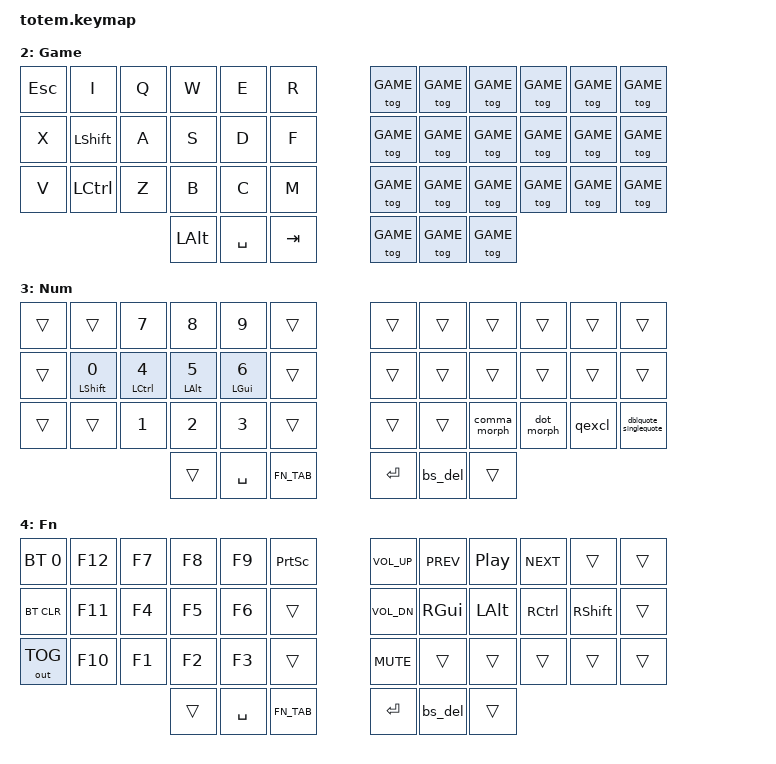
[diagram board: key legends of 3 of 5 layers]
/*
 * Zenith-ZMK Keymap
 * 42-key TOTEM variant with advanced features
 *
 * Features:
 * - Timeless homerow mods (GACS on home row)
 * - Smart num layer (num_word auto-toggle)
 * - Magic shift (repeat/sticky/capsword)
 * - Symbol combos (no dedicated symbol layer needed)
 * - Leader key sequences
 * - Gaming layer (WASD, no homerow mods)
 *
 * Layers:
 *   0 - DEF    : Base QWERTY with homerow mods
 *   1 - NAV    : Navigation, editing, media
 *   2 - GAME : Gaming (QWERTY left, no HRMs)
 *   3 - NUM    : Numbers and function keys
 *   4 - FN     : Function (reserved for future use)
 */

#include <behaviors.dtsi>
#include <behaviors/num_word.dtsi>
#include <dt-bindings/zmk/keys.h>
#include <dt-bindings/zmk/bt.h>
#include <dt-bindings/zmk/outputs.h>

/* Key position labels for 42-key layout */
#include "key-labels-42.h"

/* Swedish keyboard layout support */
#include "swedish-keys.h"

/* Layer definitions */
#define DEF 0
#define NAV 1
#define GAME 2
#define NUM 3
#define FN 4

/* Convenience aliases */
#define XXX &none
#define ___ &trans

/* Include custom behaviors, combos, and leader sequences */
#include "behaviors.dtsi"
#include "combos.dtsi"
#include "leader.dtsi"

/ {
    keymap {
        compatible = "zmk,keymap";

        /*
         * Base Layer (DEF) - QWERTY with Homerow Mods
         *
         * ╭──────┬──────┬──────┬──────┬──────┬──────╮   ╭──────┬──────┬──────┬──────┬──────┬──────╮
         * │ ESC  │  Q   │  W   │  E   │  R   │  T   │   │  Y   │  U   │  I   │  O   │  P   │  Å   │
         * ├──────┼──────┼──────┼──────┼──────┼──────┤   ├──────┼──────┼──────┼──────┼──────┼──────┤
         * │ SNIP │  A   │  S   │  D   │  F   │  G   │   │  H   │  J   │  K   │  L   │  Ö   │  Ä   │
         * │      │ SHFT │ CTRL │ ALT  │ GUI  │      │   │      │ GUI  │ ALT  │ CTRL │ SHFT │      │
         * ├──────┼──────┼──────┼──────┼──────┼──────┤   ├──────┼──────┼──────┼──────┼──────┼──────┤
         * │SEARCH│  Z   │  X   │  C   │  V   │  B   │   │  N   │  M   │  ,;  │  .:  │  ?!  │  "'  │
         * ╰──────┴──────┴──────┼──────┼──────┼──────┤   ├──────┼──────┼──────┼──────┴──────┴─────╯
         *                      │MAGIC │ SPC  │ TAB  │   │ ENTR │ BSPC │ NUM  │
         *                      │SHIFT │ NAV  │  FN  │   │      │ DEL  │      │
         *                      ╰──────┴──────┴──────╯   ╰──────┴──────┴──────╯
         */
        base_layer {
            display-name = "Base";
            bindings = <
// ╭──────────┬──────────┬──────────┬──────────┬──────────┬──────────╮   ╭──────────┬──────────┬──────────┬──────────┬──────────┬──────────╮
    &kp ESC    &kp Q      &kp W      &kp E      &kp R      &kp T          &kp Y      &kp U      &kp I      &kp O      &kp P      &kp LBKT
// ├──────────┼──────────┼──────────┼──────────┼──────────┼──────────┤   ├──────────┼──────────┼──────────┼──────────┼──────────┼──────────┤
    &kp LG(LS(S)) &hml LSHFT A &hml LCTRL S &hml LALT D &hml LGUI F &kp G   &kp H      &hmr RGUI J &hmr LALT K &hmr RCTRL L &hmr RSHFT SEMI &kp SQT
// ├──────────┼──────────┼──────────┼──────────┼──────────┼──────────┤   ├──────────┼──────────┼──────────┼──────────┼──────────┼──────────┤
    &kp LG(S)  &kp Z      &kp X      &kp C      &kp V      &kp B          &kp N      &kp M      &comma_morph &dot_morph &qexcl    &dblquote_singlequote
// ╰──────────┴──────────┴──────────┼──────────┼──────────┼──────────┤   ├──────────┼──────────┼──────────┼──────────┴──────────┴──────────╯
                                     MAGIC_SHIFT NAV_SPC    FN_TAB         &kp RET    &bs_del    SMART_NUM
//                                  ╰──────────┴──────────┴──────────╯   ╰──────────┴──────────┴──────────╯
            >;
        };

        /*
         * Navigation Layer (NAV)
         *
         * F&R- Find and replace
         * Next- Find Next
         * SWORD - Select Word
         * SALL - Select All
         * DESE - Deselect
         *
         * ╭──────┬──────┬──────┬──────┬──────┬──────╮   ╭──────┬──────┬──────┬──────┬──────┬──────╮
         * │      │ ALT4 │      │ PWIN │ NWIN │      │   │ PGUP │ FIND │  UP  │  F&R │      │      │
         * ├──────┼──────┼──────┼──────┼──────┼──────┤   ├──────┼──────┼──────┼──────┼──────┼──────┤
         * │ CAPS │ SHFT │ CTRL │ ALT  │ GUI  │      │   │ PGDN │ LEFT │ DOWN │ RGHT │      │      │
         * ├──────┼──────┼──────┼──────┼──────┼──────┤   ├──────┼──────┼──────┼──────┼──────┼──────┤
         * │      │      │AltGR │      │      │      │   │ INS  │SALL  │ SWORD│ DESE │      │      │
         * ╰──────┴──────┴──────┼──────┼──────┼──────┤   ├──────┼──────┼──────┼──────┴──────┴──────╯
         *                      │      │ SPC  │ TAB  │   │ ENTR │ BSPC │CANCEL│
         *                      │      │      │  FN  │   │      │ DEL  │      │
         *                      ╰──────┴──────┴──────╯   ╰──────┴──────┴──────╯
         */
        nav_layer {
            display-name = "Nav";
            bindings = <
// ╭──────────┬──────────┬──────────┬──────────┬──────────┬──────────╮   ╭──────────┬──────────┬──────────┬──────────┬──────────┬──────────╮
    ___        &kp LA(F4) ___        &kp LS(TAB) &swapper  ___            &kp PG_UP  &kp LC(F)  &kp UP     &kp LC(H)  ___        ___
// ├──────────┼──────────┼──────────┼──────────┼──────────┼──────────┤   ├──────────┼──────────┼──────────┼──────────┼──────────┼──────────┤
    &kp CAPS   &sk LSHFT  &sk LCTRL  &sk LALT   &sk LGUI   ___            &kp PG_DN  NAV_LEFT   &kp DOWN   NAV_RIGHT  ___        ___
// ├──────────┼──────────┼──────────┼──────────┼──────────┼──────────┤   ├──────────┼──────────┼──────────┼──────────┼──────────┼──────────┤
    ___        ___        &kp RALT   ___        ___        ___            &kp INS    &kp LC(A)  &kp LC(D)  &kp ESC    ___        ___
// ╰──────────┴──────────┴──────────┼──────────┼──────────┼──────────┤   ├──────────┼──────────┼──────────┼──────────┴──────────┴──────────╯
                                     ___        &kp SPACE  FN_TAB         &kp RET    &bs_del    CANCEL
//                                  ╰──────────┴──────────┴──────────╯   ╰──────────┴──────────┴──────────╯
            >;
        };

        /*
         * Game Layer (GAME)
         *
         * Standard QWERTY without homerow mods for gaming.
         * Right side entirely exits game mode on any keypress.
         * Toggle layer with combo: both outer top keys (LT5 + RT5)
         *
         * ╭──────┬──────┬──────┬──────┬──────┬──────╮   ╭──────┬──────┬──────┬──────┬──────┬──────╮
         * │ ESC  │  I   │  Q   │  W   │  E   │  R   │   │-GAME │-GAME │-GAME │-GAME │-GAME │-GAME │
         * ├──────┼──────┼──────┼──────┼──────┼──────┤   ├──────┼──────┼──────┼──────┼──────┼──────┤
         * │  X   │ SHFT │  A   │  S   │  D   │  F   │   │-GAME │-GAME │-GAME │-GAME │-GAME │-GAME │
         * ├──────┼──────┼──────┼──────┼──────┼──────┤   ├──────┼──────┼──────┼──────┼──────┼──────┤
         * │  V   │ CTRL │  Z   │  B   │  C   │  M   │   │-GAME │-GAME │-GAME │-GAME │-GAME │-GAME │
         * ╰──────┴──────┴──────┼──────┼──────┼──────┤   ├──────┼──────┼──────┼──────┴──────┴──────╯
         *                      │ ALT  │ SPC  │ TAB  │   │ ENTR │ BSPC │ GUI  │
         *                      ╰──────┴──────┴──────╯   ╰──────┴──────┴──────╯
         */
        game_layer {
            display-name = "Game";
            bindings = <
// ╭──────────┬──────────┬──────────┬──────────┬──────────┬──────────╮   ╭──────────┬──────────┬──────────┬──────────┬──────────┬──────────╮
    &kp ESC    &kp I      &kp Q      &kp W      &kp E      &kp R          &tog GAME  &tog GAME  &tog GAME  &tog GAME  &tog GAME  &tog GAME
// ├──────────┼──────────┼──────────┼──────────┼──────────┼──────────┤   ├──────────┼──────────┼──────────┼──────────┼──────────┼──────────┤
    &kp X      &kp LSHFT  &kp A      &kp S      &kp D      &kp F          &tog GAME  &tog GAME  &tog GAME  &tog GAME  &tog GAME  &tog GAME
// ├──────────┼──────────┼──────────┼──────────┼──────────┼──────────┤   ├──────────┼──────────┼──────────┼──────────┼──────────┼──────────┤
    &kp V      &kp LCTRL  &kp Z      &kp B      &kp C      &kp M          &tog GAME  &tog GAME  &tog GAME  &tog GAME  &tog GAME  &tog GAME
// ╰──────────┴──────────┴──────────┼──────────┼──────────┼──────────┤   ├──────────┼──────────┼──────────┼──────────┴──────────┴──────────╯
                                     &kp LALT   &kp SPACE  &kp TAB        &tog GAME  &tog GAME  &tog GAME
//                                  ╰──────────┴──────────┴──────────╯   ╰──────────┴──────────┴──────────╯
            >;
        };

        /*
         * Number Layer (NUM) - Swedish keyboard optimized
         *
         * Homerow mods: SHIFT-CTRL-ALT-GUI (same as base layer)
         * Left hand: 0=SHIFT, 4=CTRL, 5=ALT, 6=GUI | Numbers in numpad-style arrangement
         * Right hand: Empty (all keys exit to base)
         * Thumbs: Mirrors default layer
         *
         * ╭──────┬──────┬──────┬──────┬──────┬──────╮   ╭──────┬──────┬──────┬──────┬──────┬──────╮
         * │      │      │  7   │  8   │  9   │      │   │      │      │      │      │      │      │
         * ├──────┼──────┼──────┼──────┼──────┼──────┤   ├──────┼──────┼──────┼──────┼──────┼──────┤
         * │      │  0   │  4   │  5   │  6   │      │   │      │      │      │      │      │      │
         * │      │ SHFT │ CTRL │ ALT  │ GUI  │      │   │      │ GUI  │ ALT  │ CTRL │ SHFT │      │
         * ├──────┼──────┼──────┼──────┼──────┼──────┤   ├──────┼──────┼──────┼──────┼──────┼──────┤
         * │      │      │  1   │  2   │  3   │      │   │      │      │  ,;  │  .:  │  ?!  │  "'  │
         * ╰──────┴──────┴──────┼──────┼──────┼──────┤   ├──────┼──────┼──────┼──────┴──────┴──────╯
         *                      │      │ SPC  │ TAB  │   │ ENTR │ BSPC │      │
         *                      │      │      │  FN  │   │      │ DEL  │      │
         *                      ╰──────┴──────┴──────╯   ╰──────┴──────┴──────╯
         */
        num_layer {
            display-name = "Num";
            bindings = <
// ╭──────────┬──────────┬──────────┬──────────┬──────────┬──────────╮   ╭──────────┬──────────┬──────────┬──────────┬──────────┬──────────╮
    ___        ___        &kp N7     &kp N8     &kp N9     ___            ___        ___        ___        ___        ___        ___
// ├──────────┼──────────┼──────────┼──────────┼──────────┼──────────┤   ├──────────┼──────────┼──────────┼──────────┼──────────┼──────────┤
    ___   &hml LSHFT N0 &hml LCTRL N4 &hml LALT N5 &hml LGUI N6 ___        ___        ___        ___        ___        ___        ___
// ├──────────┼──────────┼──────────┼──────────┼──────────┼──────────┤   ├──────────┼──────────┼──────────┼──────────┼──────────┼──────────┤
    ___        ___        &kp N1     &kp N2     &kp N3     ___            ___        ___        &comma_morph &dot_morph &qexcl    &dblquote_singlequote
// ╰──────────┴──────────┴──────────┼──────────┼──────────┼──────────┤   ├──────────┼──────────┼──────────┼──────────┴──────────┴──────────╯
                                     ___        &kp SPACE  FN_TAB         &kp RET    &bs_del    ___
//                                  ╰──────────┴──────────┴──────────╯   ╰──────────┴──────────┴──────────╯
            >;
        };

        /*
         * Function Layer (FN)
         *
         * Left: F1-F12 keys + Bluetooth controls (left side is central/host)
         * Right: Multimedia controls (volume, media)
         * Thumbs: Same as NUM layer
         *
         * ╭──────┬──────┬──────┬──────┬──────┬──────╮   ╭──────┬──────┬──────┬──────┬──────┬──────╮
         * │  BT0 │  F12 │  F7  │ F8   │ F9   │PSCRN │   │ VOL+ │ PREV │ PLAY │ NEXT │      │      │
         * ├──────┼──────┼──────┼──────┼──────┼──────┤   ├──────┼──────┼──────┼──────┼──────┼──────┤
         * │ BTCLR│  F11 │  F4  │  F5  │  F6  │      │   │ VOL- │ GUI  │ ALT  │ CTRL │ SHFT │      │
         * ├──────┼──────┼──────┼──────┼──────┼──────┤   ├──────┼──────┼──────┼──────┼──────┼──────┤
         * │OUTTOG│  F10 │  F1  │  F2  │  F3  │      │   │ MUTE │      │      │      │      │      │
         * ╰──────┴──────┴──────┼──────┼──────┼──────┤   ├──────┼──────┼──────┼──────┴──────┴──────╯
         *                      │      │ SPC  │ TAB  │   │ ENTR │ BSPC │      │
         *                      │      │      │  FN  │   │      │ DEL  │      │
         *                      ╰──────┴──────┴──────╯   ╰──────┴──────┴──────╯
         */
        fn_layer {
            display-name = "Fn";
            bindings = <
// ╭──────────┬──────────┬──────────┬──────────┬──────────┬──────────╮   ╭──────────┬──────────┬──────────┬──────────┬──────────┬──────────╮
    &bt BT_SEL 0 &kp F12  &kp F7     &kp F8     &kp F9     &kp PSCRN      &kp C_VOL_UP &kp C_PREV &kp C_PP  &kp C_NEXT ___        ___
// ├──────────┼──────────┼──────────┼──────────┼──────────┼──────────┤   ├──────────┼──────────┼──────────┼──────────┼──────────┼──────────┤
    &bt BT_CLR &kp F11    &kp F4     &kp F5     &kp F6     ___            &kp C_VOL_DN &kp RGUI   &kp LALT   &kp RCTRL  &kp RSHFT  ___
// ├──────────┼──────────┼──────────┼──────────┼──────────┼──────────┤   ├──────────┼──────────┼──────────┼──────────┼──────────┼──────────┤
    &out OUT_TOG &kp F10  &kp F1     &kp F2     &kp F3     ___            &kp C_MUTE ___        ___        ___        ___        ___
// ╰──────────┴──────────┴──────────┼──────────┼──────────┼──────────┤   ├──────────┼──────────┼──────────┼──────────┴──────────┴──────────╯
                                     ___        &kp SPACE  FN_TAB         &kp RET    &bs_del    ___
//                                  ╰──────────┴──────────┴──────────╯   ╰──────────┴──────────┴──────────╯
            >;
        };
    };
};
